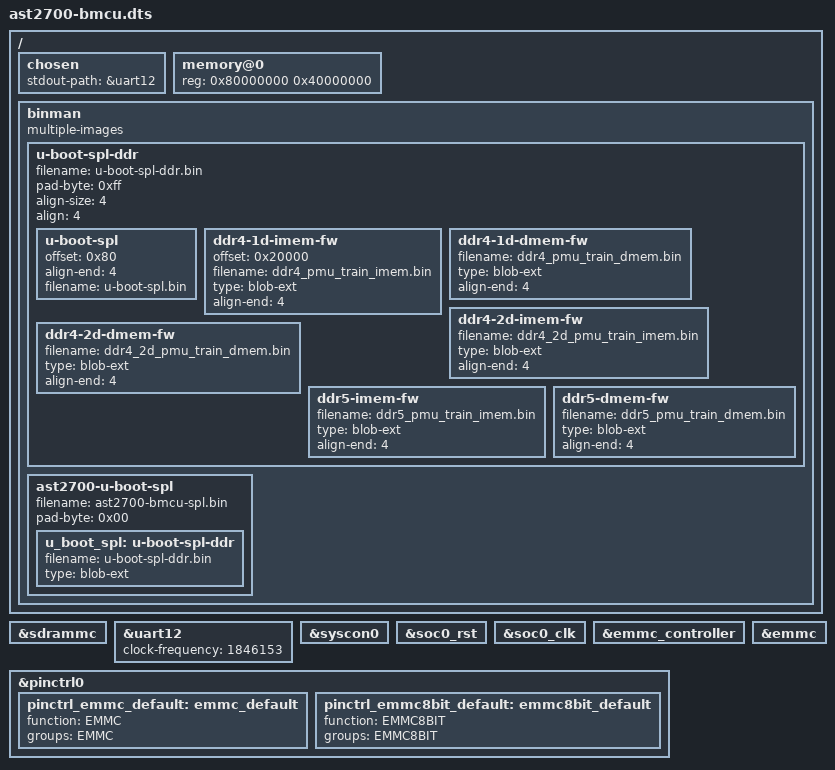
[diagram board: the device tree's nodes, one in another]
// SPDX-License-Identifier: (GPL-2.0 OR MIT)

/dts-v1/;

#include "ast2700.dtsi"

/ {
	chosen {
		stdout-path = &uart12;
	};

	memory@0 {
		device_type = "memory";
		reg = <0x80000000 0x40000000>;
	};

	binman: binman {
		multiple-images;
	};
};

&sdrammc {
	status = "okay";
	bootph-all;
};

&uart12 {
	status = "okay";
	clock-frequency = <1846153>;
};

&syscon0 {
	bootph-all;
	status = "okay";
};

&soc0_rst {
	bootph-all;
};

&soc0_clk {
	bootph-all;
};

&emmc_controller {
	bootph-all;
	status = "okay";
};

&emmc {
	bootph-all;
	status = "okay";
};

&pinctrl0 {
	pinctrl_emmc_default: emmc_default {
		function = "EMMC";
		groups = "EMMC";
	};

	pinctrl_emmc8bit_default: emmc8bit_default {
		function = "EMMC8BIT";
		groups = "EMMC8BIT";
	};
};

&binman {
	bootph-all;

	u-boot-spl-ddr {
		bootph-all;
		filename = "u-boot-spl-ddr.bin";
		pad-byte = <0xff>;
		align-size = <4>;
		align = <4>;

		u-boot-spl {
			offset = <0x80>;
			bootph-all;
			align-end = <4>;
			filename = "u-boot-spl.bin";
		};

		ddr4-1d-imem-fw {
			offset = <0x20000>;
			bootph-all;
			filename = "ddr4_pmu_train_imem.bin";
			type = "blob-ext";
			align-end = <4>;
		};
		ddr4-1d-dmem-fw {
			bootph-all;
			filename = "ddr4_pmu_train_dmem.bin";
			type = "blob-ext";
			align-end = <4>;
		};
		ddr4-2d-imem-fw {
			bootph-all;
			filename = "ddr4_2d_pmu_train_imem.bin";
			type = "blob-ext";
			align-end = <4>;
		};
		ddr4-2d-dmem-fw {
			bootph-all;
			filename = "ddr4_2d_pmu_train_dmem.bin";
			type = "blob-ext";
			align-end = <4>;
		};
		ddr5-imem-fw {
			bootph-all;
			filename = "ddr5_pmu_train_imem.bin";
			type = "blob-ext";
			align-end = <4>;
		};
		ddr5-dmem-fw {
			bootph-all;
			filename = "ddr5_pmu_train_dmem.bin";
			type = "blob-ext";
			align-end = <4>;
		};
	};

	ast2700-u-boot-spl {
		bootph-all;
		filename = "ast2700-bmcu-spl.bin";
		pad-byte = <0x00>;

//		pre-load {
//			content = <&u_boot_spl>;
//			algo-name = "sha256,rsa2048";
//			key-name = "keys/dev.key";
//			header-size = <1024>;
//			version = <1>;
//		};

		u_boot_spl: u-boot-spl-ddr {
			bootph-all;
			filename = "u-boot-spl-ddr.bin";
			type = "blob-ext";
		};
	};
};
